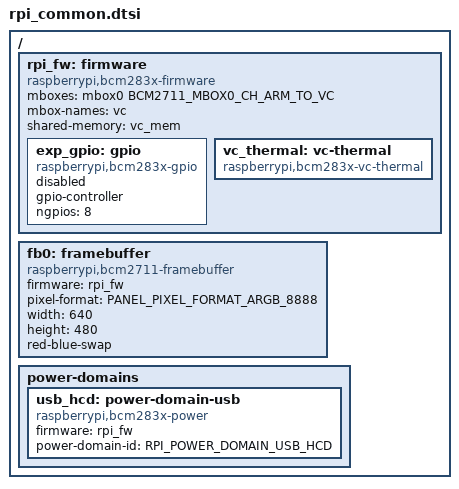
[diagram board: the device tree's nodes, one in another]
/*
 * Copyright (c) 2026 Muhammad Waleed Badar
 *
 * SPDX-License-Identifier: Apache-2.0
 */

#include <zephyr/dt-bindings/display/panel.h>
#include <zephyr/dt-bindings/mbox/brcm-bcm2711-mbox.h>
#include <zephyr/dt-bindings/power/rpi_bcm283x_power.h>

/ {
	rpi_fw: firmware {
		compatible = "raspberrypi,bcm283x-firmware";
		mboxes = <&mbox0 BCM2711_MBOX0_CH_ARM_TO_VC>;
		mbox-names = "vc";
		shared-memory = <&vc_mem>;

		exp_gpio: gpio {
			compatible = "raspberrypi,bcm283x-gpio";
			gpio-controller;
			#gpio-cells = <2>;
			ngpios = <8>;
			status = "disabled";
		};

		vc_thermal: vc-thermal {
			compatible = "raspberrypi,bcm283x-vc-thermal";
			status = "okay";
		};
	};

	fb0: framebuffer {
		compatible = "raspberrypi,bcm2711-framebuffer";
		firmware = <&rpi_fw>;
		pixel-format = <PANEL_PIXEL_FORMAT_ARGB_8888>;
		width = <640>;
		height = <480>;
		red-blue-swap;
	};

	power-domains {
		usb_hcd: power-domain-usb {
			compatible = "raspberrypi,bcm283x-power";
			firmware = <&rpi_fw>;
			#power-domain-cells = <0>;
			power-domain-id = <RPI_POWER_DOMAIN_USB_HCD>;
		};
	};
};
